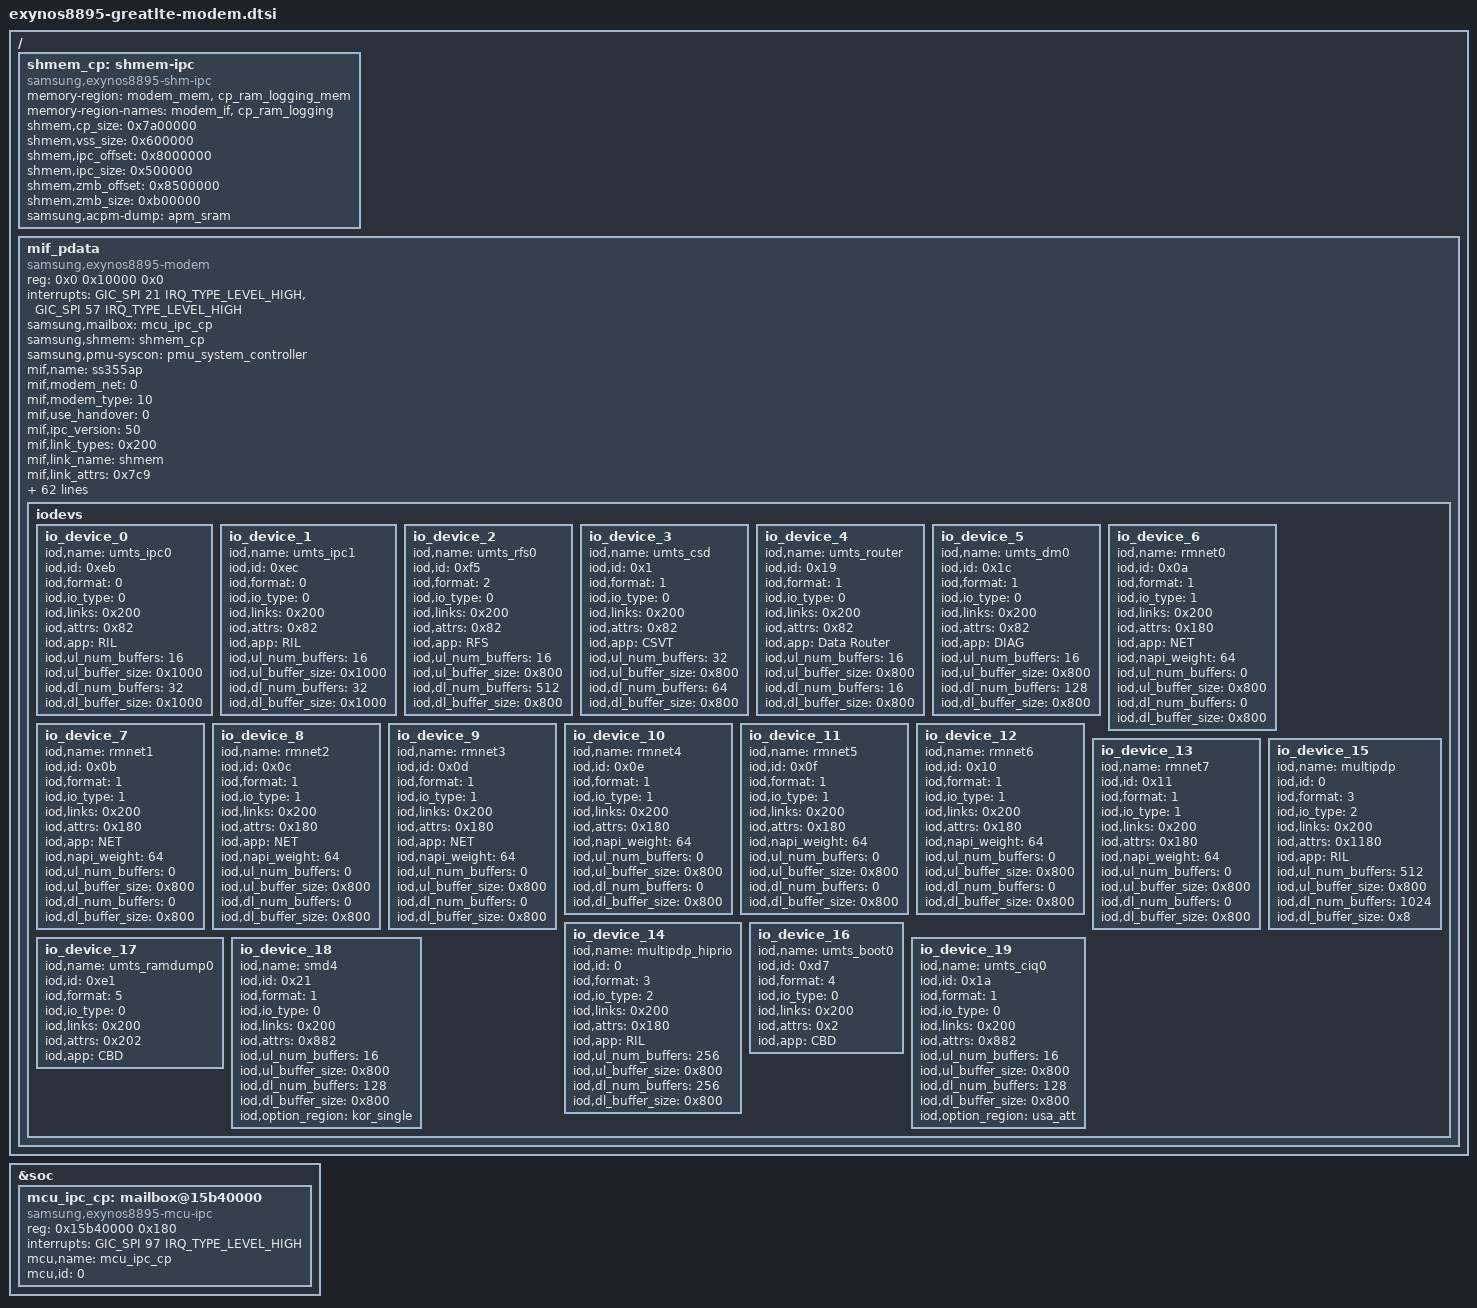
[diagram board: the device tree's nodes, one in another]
// SPDX-License-Identifier: GPL-2.0 OR BSD-3-Clause
/*
 * Samsung Galaxy Note 8 (SM-N950N) modem
 */

#include <dt-bindings/gpio/gpio.h>

/ {
	shmem_cp: shmem-ipc {
		compatible = "samsung,exynos8895-shm-ipc";
		memory-region = <&modem_mem>, <&cp_ram_logging_mem>;
		memory-region-names = "modem_if", "cp_ram_logging";
		shmem,cp_size = <0x7a00000>;
		shmem,vss_size = <0x600000>;
		shmem,ipc_offset = <0x8000000>;
		shmem,ipc_size = <0x500000>;
		shmem,zmb_offset = <0x8500000>;
		shmem,zmb_size = <0xb00000>;
		samsung,acpm-dump = <&apm_sram>;
	};

	mif_pdata {
		compatible = "samsung,exynos8895-modem";
		reg = <0x0 0x10000 0x0>;
		interrupts = <GIC_SPI 21 IRQ_TYPE_LEVEL_HIGH>,
			     <GIC_SPI 57 IRQ_TYPE_LEVEL_HIGH>;
		samsung,mailbox = <&mcu_ipc_cp>;
		samsung,shmem = <&shmem_cp>;
		samsung,pmu-syscon = <&pmu_system_controller>;
		mif,name = "ss355ap";
		mif,modem_net = <0>;
		mif,modem_type = <10>;
		mif,use_handover = <0>;
		mif,ipc_version = <50>;
		mif,link_types = <0x200>;
		mif,link_name = "shmem";
		mif,link_attrs = <0x7c9>;
		mif,num_iodevs = <20>;
		mif,buff_offset = <0x500000>;
		mif,buff_size = <0x900000>;
		mif,bufpool_2nd_base = <0xe9000000>;
		mif,bufpool_2nd_size = <0x4000000>;
		mbx_ap2cp_msg = <0>;
		mbx_cp2ap_msg = <1>;
		mbx_ap2cp_united_status = <2>;
		mbx_cp2ap_united_status = <3>;
		mbx_ap2cp_mif_value = <4>;
		mbx_ap2cp_kerneltime = <9>;
		mif,int_ap2cp_msg = <0>;
		mif,int_ap2cp_wakeup = <1>;
		mif,int_ap2cp_status = <2>;
		mif,int_ap2cp_active = <3>;
		mif,irq_cp2ap_msg = <0>;
		mif,irq_cp2ap_status = <2>;
		mif,irq_cp2ap_active = <4>;
		mif,irq_cp2ap_wakelock = <8>;
		mif,irq_cp2ap_ratmode = <9>;
		mbx_cp2ap_dvfsreq_cpu = <5>;
		mbx_cp2ap_dvfsreq_mif = <6>;
		mbx_cp2ap_dvfsreq_int = <7>;
		mif,irq_cp2ap_perf_req_cpu = <5>;
		mif,irq_cp2ap_perf_req_mif = <6>;
		mif,irq_cp2ap_perf_req_int = <7>;
		sbi_cp_rat_mode_mask = <0x3f>;
		sbi_cp_rat_mode_pos = <26>;
		sbi_cp_evs_mode_mask = <0x1>;
		sbi_cp_evs_mode_pos = <7>;
		sbi_cp_wakelock_mask = <0x1>;
		sbi_cp_wakelock_pos = <6>;
		sbi_lte_active_mask = <0x1>;
		sbi_lte_active_pos = <5>;
		sbi_cp_status_mask = <0xf>;
		sbi_cp_status_pos = <1>;
		sbi_cp2ap_wakelock_mask = <0x1>;
		sbi_cp2ap_wakelock_pos = <6>;
		sbi_pda_active_mask = <0x1>;
		sbi_pda_active_pos = <5>;
		sbi_ap_status_mask = <0xf>;
		sbi_ap_status_pos = <1>;
		sbi_crash_type_mask = <0xf>;
		sbi_crash_type_pos = <23>;
		sbi_device_type_mask = <0x1f>;
		sbi_device_type_pos = <18>;
		sbi_ext_backtrace_mask = <0x1>;
		sbi_ext_backtrace_pos = <17>;
		sbi_ds_det_mask = <0x3>;
		sbi_ds_det_pos = <14>;
		sbi_sys_rev_mask = <0xff>;
		sbi_sys_rev_pos = <6>;
		sbi_lockval_cp2ap_dvfsreq_endian_mask = <0x1>;
		sbi_lockval_cp2ap_dvfsreq_endian_pos = <31>;
		sbi_lockval_cp2ap_dvfsreq_index_mask = <0x7fff>;
		sbi_lockval_cp2ap_dvfsreq_index_pos = <0>;
		sbi_ap2cp_kerneltime_sec_mask = <0xfff>;
		sbi_ap2cp_kerneltime_sec_pos = <20>;
		sbi_ap2cp_kerneltime_usec_mask = <0xfffff>;
		sbi_ap2cp_kerneltime_usec_pos = <0>;
		gpios = <&gpf1 1 GPIO_ACTIVE_HIGH>, <&gpf1 2 GPIO_ACTIVE_HIGH>,
			<&gpf1 3 GPIO_ACTIVE_HIGH>, <&gpf1 7 GPIO_ACTIVE_HIGH>,
			<&gpd0 0 GPIO_ACTIVE_HIGH>, <&gpd0 1 GPIO_ACTIVE_HIGH>,
			<&gpd0 2 GPIO_ACTIVE_HIGH>, <&gpd0 3 GPIO_ACTIVE_HIGH>;

		iodevs {
			io_device_0 {
				iod,name = "umts_ipc0";
				iod,id = <0xeb>;
				iod,format = <0>;
				iod,io_type = <0>;
				iod,links = <0x200>;
				iod,attrs = <0x82>;
				iod,app = "RIL";
				iod,ul_num_buffers = <16>;
				iod,ul_buffer_size = <0x1000>;
				iod,dl_num_buffers = <32>;
				iod,dl_buffer_size = <0x1000>;
			};

			io_device_1 {
				iod,name = "umts_ipc1";
				iod,id = <0xec>;
				iod,format = <0>;
				iod,io_type = <0>;
				iod,links = <0x200>;
				iod,attrs = <0x82>;
				iod,app = "RIL";
				iod,ul_num_buffers = <16>;
				iod,ul_buffer_size = <0x1000>;
				iod,dl_num_buffers = <32>;
				iod,dl_buffer_size = <0x1000>;
			};

			io_device_2 {
				iod,name = "umts_rfs0";
				iod,id = <0xf5>;
				iod,format = <2>;
				iod,io_type = <0>;
				iod,links = <0x200>;
				iod,attrs = <0x82>;
				iod,app = "RFS";
				iod,ul_num_buffers = <16>;
				iod,ul_buffer_size = <0x800>;
				iod,dl_num_buffers = <512>;
				iod,dl_buffer_size = <0x800>;
			};

			io_device_3 {
				iod,name = "umts_csd";
				iod,id = <0x1>;
				iod,format = <1>;
				iod,io_type = <0>;
				iod,links = <0x200>;
				iod,attrs = <0x82>;
				iod,app = "CSVT";
				iod,ul_num_buffers = <32>;
				iod,ul_buffer_size = <0x800>;
				iod,dl_num_buffers = <64>;
				iod,dl_buffer_size = <0x800>;
			};

			io_device_4 {
				iod,name = "umts_router";
				iod,id = <0x19>;
				iod,format = <1>;
				iod,io_type = <0>;
				iod,links = <0x200>;
				iod,attrs = <0x82>;
				iod,app = "Data Router";
				iod,ul_num_buffers = <16>;
				iod,ul_buffer_size = <0x800>;
				iod,dl_num_buffers = <16>;
				iod,dl_buffer_size = <0x800>;
			};

			io_device_5 {
				iod,name = "umts_dm0";
				iod,id = <0x1c>;
				iod,format = <1>;
				iod,io_type = <0>;
				iod,links = <0x200>;
				iod,attrs = <0x82>;
				iod,app = "DIAG";
				iod,ul_num_buffers = <16>;
				iod,ul_buffer_size = <0x800>;
				iod,dl_num_buffers = <128>;
				iod,dl_buffer_size = <0x800>;
			};

			io_device_6 {
				iod,name = "rmnet0";
				iod,id = <0x0a>;
				iod,format = <1>;
				iod,io_type = <1>;
				iod,links = <0x200>;
				iod,attrs = <0x180>;
				iod,app = "NET";
				iod,napi_weight = <64>;
				iod,ul_num_buffers = <0>;
				iod,ul_buffer_size = <0x800>;
				iod,dl_num_buffers = <0>;
				iod,dl_buffer_size = <0x800>;
			};

			io_device_7 {
				iod,name = "rmnet1";
				iod,id = <0x0b>;
				iod,format = <1>;
				iod,io_type = <1>;
				iod,links = <0x200>;
				iod,attrs = <0x180>;
				iod,app = "NET";
				iod,napi_weight = <64>;
				iod,ul_num_buffers = <0>;
				iod,ul_buffer_size = <0x800>;
				iod,dl_num_buffers = <0>;
				iod,dl_buffer_size = <0x800>;
			};

			io_device_8 {
				iod,name = "rmnet2";
				iod,id = <0x0c>;
				iod,format = <1>;
				iod,io_type = <1>;
				iod,links = <0x200>;
				iod,attrs = <0x180>;
				iod,app = "NET";
				iod,napi_weight = <64>;
				iod,ul_num_buffers = <0>;
				iod,ul_buffer_size = <0x800>;
				iod,dl_num_buffers = <0>;
				iod,dl_buffer_size = <0x800>;
			};

			io_device_9 {
				iod,name = "rmnet3";
				iod,id = <0x0d>;
				iod,format = <1>;
				iod,io_type = <1>;
				iod,links = <0x200>;
				iod,attrs = <0x180>;
				iod,app = "NET";
				iod,napi_weight = <64>;
				iod,ul_num_buffers = <0>;
				iod,ul_buffer_size = <0x800>;
				iod,dl_num_buffers = <0>;
				iod,dl_buffer_size = <0x800>;
			};

			io_device_10 {
				iod,name = "rmnet4";
				iod,id = <0x0e>;
				iod,format = <1>;
				iod,io_type = <1>;
				iod,links = <0x200>;
				iod,attrs = <0x180>;
				iod,napi_weight = <64>;
				iod,ul_num_buffers = <0>;
				iod,ul_buffer_size = <0x800>;
				iod,dl_num_buffers = <0>;
				iod,dl_buffer_size = <0x800>;
			};

			io_device_11 {
				iod,name = "rmnet5";
				iod,id = <0x0f>;
				iod,format = <1>;
				iod,io_type = <1>;
				iod,links = <0x200>;
				iod,attrs = <0x180>;
				iod,napi_weight = <64>;
				iod,ul_num_buffers = <0>;
				iod,ul_buffer_size = <0x800>;
				iod,dl_num_buffers = <0>;
				iod,dl_buffer_size = <0x800>;
			};

			io_device_12 {
				iod,name = "rmnet6";
				iod,id = <0x10>;
				iod,format = <1>;
				iod,io_type = <1>;
				iod,links = <0x200>;
				iod,attrs = <0x180>;
				iod,napi_weight = <64>;
				iod,ul_num_buffers = <0>;
				iod,ul_buffer_size = <0x800>;
				iod,dl_num_buffers = <0>;
				iod,dl_buffer_size = <0x800>;
			};

			io_device_13 {
				iod,name = "rmnet7";
				iod,id = <0x11>;
				iod,format = <1>;
				iod,io_type = <1>;
				iod,links = <0x200>;
				iod,attrs = <0x180>;
				iod,napi_weight = <64>;
				iod,ul_num_buffers = <0>;
				iod,ul_buffer_size = <0x800>;
				iod,dl_num_buffers = <0>;
				iod,dl_buffer_size = <0x800>;
			};

			io_device_14 {
				iod,name = "multipdp_hiprio";
				iod,id = <0>;
				iod,format = <3>;
				iod,io_type = <2>;
				iod,links = <0x200>;
				iod,attrs = <0x180>;
				iod,app = "RIL";
				iod,ul_num_buffers = <256>;
				iod,ul_buffer_size = <0x800>;
				iod,dl_num_buffers = <256>;
				iod,dl_buffer_size = <0x800>;
			};

			io_device_15 {
				iod,name = "multipdp";
				iod,id = <0>;
				iod,format = <3>;
				iod,io_type = <2>;
				iod,links = <0x200>;
				iod,attrs = <0x1180>;
				iod,app = "RIL";
				iod,ul_num_buffers = <512>;
				iod,ul_buffer_size = <0x800>;
				iod,dl_num_buffers = <1024>;
				iod,dl_buffer_size = <0x8>;
			};

			io_device_16 {
				iod,name = "umts_boot0";
				iod,id = <0xd7>;
				iod,format = <4>;
				iod,io_type = <0>;
				iod,links = <0x200>;
				iod,attrs = <0x2>;
				iod,app = "CBD";
			};

			io_device_17 {
				iod,name = "umts_ramdump0";
				iod,id = <0xe1>;
				iod,format = <5>;
				iod,io_type = <0>;
				iod,links = <0x200>;
				iod,attrs = <0x202>;
				iod,app = "CBD";
			};

			io_device_18 {
				iod,name = "smd4";
				iod,id = <0x21>;
				iod,format = <1>;
				iod,io_type = <0>;
				iod,links = <0x200>;
				iod,attrs = <0x882>;
				iod,ul_num_buffers = <16>;
				iod,ul_buffer_size = <0x800>;
				iod,dl_num_buffers = <128>;
				iod,dl_buffer_size = <0x800>;
				iod,option_region = "kor_single";
			};

			io_device_19 {
				iod,name = "umts_ciq0";
				iod,id = <0x1a>;
				iod,format = <1>;
				iod,io_type = <0>;
				iod,links = <0x200>;
				iod,attrs = <0x882>;
				iod,ul_num_buffers = <16>;
				iod,ul_buffer_size = <0x800>;
				iod,dl_num_buffers = <128>;
				iod,dl_buffer_size = <0x800>;
				iod,option_region = "usa_att";
			};
		};
	};
};

&soc {
	mcu_ipc_cp: mailbox@15b40000 {
		compatible = "samsung,exynos8895-mcu-ipc";
		reg = <0x15b40000 0x180>;
		interrupts = <GIC_SPI 97 IRQ_TYPE_LEVEL_HIGH>;
		mcu,name = "mcu_ipc_cp";
		mcu,id = <0>;
	};
};
